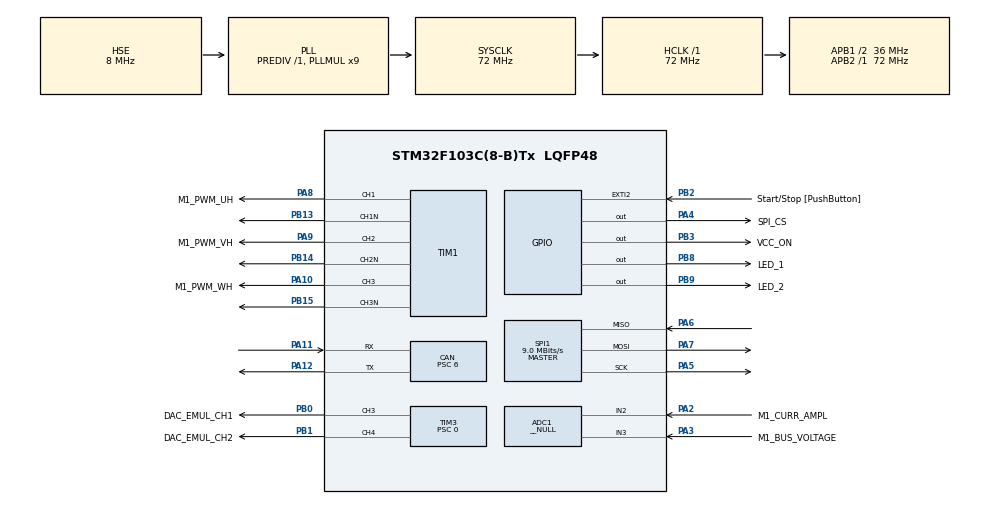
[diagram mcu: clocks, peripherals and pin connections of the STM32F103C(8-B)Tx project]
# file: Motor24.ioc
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ADC1.Channel-1\#ChannelInjectedConversion=ADC_CHANNEL_2
ADC1.Channel-1\#ChannelRegularConversion=ADC_CHANNEL_3
ADC1.Channel-2\#ChannelInjectedConversion=ADC_CHANNEL_2
ADC1.ContinuousConvMode=DISABLE
ADC1.DataAlign=ADC_DATAALIGN_LEFT
ADC1.DiscontinuousConvMode=DISABLE
ADC1.EnableAnalogWatchDog=false
ADC1.EnableInjectedConversion=ENABLE
ADC1.EnableRegularConversion=ENABLE
ADC1.ExternalTrigConv=ADC_SOFTWARE_START
ADC1.ExternalTrigConvEdge=ADC_EXTERNALTRIGCONVEDGE_NONE
ADC1.ExternalTrigInjecConv=ADC_EXTERNALTRIGINJECCONV_T4_TRGO
ADC1.ExternalTrigInjecConvEdge=ADC_EXTERNALTRIGINJECCONVEDGE_RISING
ADC1.InjNumberOfConversion=2
ADC1.InjectedConvMode=None
ADC1.InjectedOffset-1\#ChannelInjectedConversion=0
ADC1.InjectedOffset-2\#ChannelInjectedConversion=0
ADC1.Mode=__NULL
ADC1.NbrOfConversion=1
ADC1.NbrOfConversionFlag=1
ADC1.Offset-1\#ChannelRegularConversion=0
ADC1.OffsetNumber-1\#ChannelRegularConversion=ADC_OFFSET_NONE
ADC1.Rank-1\#ChannelInjectedConversion=1
ADC1.Rank-1\#ChannelRegularConversion=1
ADC1.Rank-2\#ChannelInjectedConversion=2
ADC1.SamplingTime-1\#ChannelInjectedConversion=ADC_SAMPLETIME_7CYCLES_5
ADC1.SamplingTime-1\#ChannelRegularConversion=ADC_SAMPLETIME_28CYCLES_5
ADC1.SamplingTime-2\#ChannelInjectedConversion=ADC_SAMPLETIME_7CYCLES_5
ADC1.ScanConvMode=ADC_SCAN_ENABLE
ADC1.master=1
CAN.BS1=CAN_BS1_3TQ
CAN.BS2=CAN_BS2_2TQ
CAN.CalculateTimeBit=1000
CAN.CalculateTimeQuantum=166.66666666666669
CAN.Prescaler=6
Dma.ADC1.2.Direction=DMA_PERIPH_TO_MEMORY
Dma.ADC1.2.Instance=DMA1_Channel1
Dma.ADC1.2.MemDataAlignment=DMA_MDATAALIGN_HALFWORD
Dma.ADC1.2.MemInc=DMA_MINC_DISABLE
Dma.ADC1.2.Mode=DMA_CIRCULAR
Dma.ADC1.2.PeriphDataAlignment=DMA_PDATAALIGN_HALFWORD
Dma.ADC1.2.PeriphInc=DMA_PINC_DISABLE
Dma.ADC1.2.Priority=DMA_PRIORITY_LOW
Dma.Request0=TIM1_UP
Dma.Request1=TIM1_CH4/TRIG/COM
Dma.Request2=ADC1
Dma.TIM1_CH4/TRIG/COM.1.Direction=DMA_MEMORY_TO_PERIPH
Dma.TIM1_CH4/TRIG/COM.1.Instance=DMA1_Channel4
Dma.TIM1_CH4/TRIG/COM.1.MemDataAlignment=DMA_MDATAALIGN_HALFWORD
Dma.TIM1_CH4/TRIG/COM.1.MemInc=DMA_MINC_ENABLE
Dma.TIM1_CH4/TRIG/COM.1.Mode=DMA_CIRCULAR
Dma.TIM1_CH4/TRIG/COM.1.PeriphDataAlignment=DMA_PDATAALIGN_HALFWORD
Dma.TIM1_CH4/TRIG/COM.1.PeriphInc=DMA_PINC_DISABLE
Dma.TIM1_CH4/TRIG/COM.1.Priority=DMA_PRIORITY_HIGH
Dma.TIM1_UP.0.Direction=DMA_MEMORY_TO_PERIPH
Dma.TIM1_UP.0.Instance=DMA1_Channel5
Dma.TIM1_UP.0.MemDataAlignment=DMA_MDATAALIGN_HALFWORD
Dma.TIM1_UP.0.MemInc=DMA_MINC_ENABLE
Dma.TIM1_UP.0.Mode=DMA_CIRCULAR
Dma.TIM1_UP.0.PeriphDataAlignment=DMA_PDATAALIGN_HALFWORD
Dma.TIM1_UP.0.PeriphInc=DMA_PINC_DISABLE
Dma.TIM1_UP.0.Priority=DMA_PRIORITY_HIGH
ExtraMW=MotorControl
ExtraMW.MotorControl.Config=MotorControl
ExtraMW.MotorControl.Mode=MotorControl
ExtraMW.MotorControl.Root=MCSDK_v5.3.3/MotorControl
ExtraMW.MotorControl.Template=templates
Mcu.Family=STM32F1
Mcu.Name=STM32F103C(8-B)Tx
Mcu.Package=LQFP48
MotorControl.ADC_1_PERIPH=ADC1
MotorControl.ADC_2_PERIPH=ADC2
MotorControl.ADC_AHBPERIPH=RCC_AHBPeriph_ADC12
MotorControl.ADC_CLOCK_WB_DIV=1
MotorControl.ADC_CLOCK_WB_FREQ=12
MotorControl.ADC_PERIPH=ADC1
MotorControl.ADC_REFERENCE_VOLTAGE=3.30
MotorControl.ALIGNMENT_ANGLE_DEG=90
MotorControl.ALIGNMENT_DURATION=700
MotorControl.AMPLIFICATION_GAIN=11.00
MotorControl.ANGC={0,0,0,0,0,0,0,0}
MotorControl.BEMF_CONSISTENCY_GAIN=64
MotorControl.BEMF_CONSISTENCY_TOL=64
MotorControl.BKIN1_FILTER=0
MotorControl.BKIN2_FILTER=0
MotorControl.BKIN2_MODE=NONE
MotorControl.BKIN_MODE=EXT_MODE
MotorControl.BOARD=CUSTOM
MotorControl.BRKIN2_GPIO_AF=GPIO_AF_2
MotorControl.BRKIN_GPIO_AF=GPIO_AF_2
MotorControl.BUS_VOLTAGE_READING=true
MotorControl.CLOCK_FREQUENCY=CPU_CLK_72_MHZ
MotorControl.CLOCK_SOURCE=EXTERNAL
MotorControl.CONSTANT1_D=2924
MotorControl.CONSTANT1_Q=2924
MotorControl.CONSTANT2_QD=3136
MotorControl.CORD_BEMF_CONSISTENCY_GAIN=64
MotorControl.CORD_BEMF_CONSISTENCY_TOL=64
MotorControl.CORD_F1=1024
MotorControl.CORD_F2=16384
MotorControl.CORD_FIFO_DEPTH_01HZ=64
MotorControl.CORD_FIFO_DEPTH_DPP=64
MotorControl.CORD_GAIN1=-410
MotorControl.CORD_GAIN2=4116
MotorControl.CORD_MAX_ACCEL_DPPP=810
MotorControl.CORD_MEAS_ERRORS_BEFORE_FAULTS=3
MotorControl.CORD_VARIANCE_THRESHOLD=4
MotorControl.CPU_CLK_72_MHZ=true
MotorControl.CTRBDID=10000
MotorControl.CURRENT_READING_TOPOLOGY=SINGLE_SHUNT
MotorControl.CURR_SAMPLING_TIME=7
MotorControl.DAC_EMULATED=true
MotorControl.DAC_FUNCTIONALITY=true
MotorControl.DAC_TIMER_CH1_GPIO_PIN=LL_GPIO_PIN_0
MotorControl.DAC_TIMER_CH1_GPIO_PORT=GPIOB
MotorControl.DAC_TIMER_CH2_GPIO_PIN=LL_GPIO_PIN_1
MotorControl.DAC_TIMER_CH2_GPIO_PORT=GPIOB
MotorControl.DAC_TIMER_REMAPPING=NO_REMAP
MotorControl.DAC_TIMER_SELECTION=TIM3
MotorControl.DC_CURRENT_RS_MEAS=1.50
MotorControl.DEBUG_DAC_CH1=true
MotorControl.DEBUG_DAC_CH2=true
MotorControl.DEFAULT_CONTROL_MODE=STC_SPEED_MODE
MotorControl.DEFAULT_DAC_CHANNEL_1=MC_PROTOCOL_REG_I_A
MotorControl.DEFAULT_DAC_CHANNEL_2=MC_PROTOCOL_REG_I_B
MotorControl.DEFAULT_DAC_MOTOR=0
MotorControl.DEFAULT_FLUX_COMPONENT=0
MotorControl.DEFAULT_TARGET_SPEED_RPM=700
MotorControl.DEFAULT_TORQUE_COMPONENT=0
MotorControl.DISSIPATIVE_BRAKE_POLARITY=DOUT_ACTIVE_HIGH
MotorControl.DRIVES_NUMBER_SELECTION=SINGLEDRIVE
MotorControl.EMERGENCY2_STOP_GPIO_PIN=LL_GPIO_PIN_12
MotorControl.EMERGENCY2_STOP_GPIO_PORT=GPIOB
MotorControl.EMERGENCY_STOP_GPIO_PIN=LL_GPIO_PIN_12
MotorControl.EMERGENCY_STOP_GPIO_PORT=GPIOB
MotorControl.ENABLE_SL_ALGO_FROM_PHASE=2
MotorControl.ENCODER_AVAILABLE=false
MotorControl.ENCODER_PPR=400
MotorControl.ENC_AVERAGING_FIFO_DEPTH=16
MotorControl.ENC_A_GPIO_PIN=LL_GPIO_PIN_0
MotorControl.ENC_A_GPIO_PORT=GPIOA
MotorControl.ENC_B_GPIO_PIN=LL_GPIO_PIN_1
MotorControl.ENC_B_GPIO_PORT=GPIOA
MotorControl.ENC_ICx_FILTER=50
MotorControl.ENC_INVERT_SPEED=false
MotorControl.ENC_MEAS_ERRORS_BEFORE_FAULTS=3
MotorControl.ENC_TIMER_REMAPPING=NO_REMAP_TIM2
MotorControl.ENC_TIMER_SELECTION=ENC_TIM2
MotorControl.EXT_CLK_8_MHZ=true
MotorControl.EXT_CLOCK_FREQUENCY=EXT_CLK_8_MHZ
MotorControl.F1=1024
MotorControl.F2=16384
MotorControl.FEEDBACK_NET_FILTERING=false
MotorControl.FEED_FORWARD_CURRENT_REG_ENABLING=false
MotorControl.FINAL_I_ALIGNMENT=4259
MotorControl.FLUX_WEAKENING_ENABLING=false
MotorControl.FW_KIDIV=32768
MotorControl.FW_KI_GAIN=5000
MotorControl.FW_KPDIV=32768
MotorControl.FW_KP_GAIN=3000
MotorControl.FW_VOLTAGE_REF=985
MotorControl.GAIN1=-410
MotorControl.GAIN2=4116
MotorControl.H1_GPIO_PIN=LL_GPIO_PIN_0
MotorControl.H1_GPIO_PORT=GPIOA
MotorControl.H2_GPIO_PIN=LL_GPIO_PIN_1
MotorControl.H2_GPIO_PORT=GPIOA
MotorControl.H3_GPIO_PIN=LL_GPIO_PIN_2
MotorControl.H3_GPIO_PORT=GPIOA
MotorControl.HALL_AVERAGING_FIFO_DEPTH=6
MotorControl.HALL_ICx_FILTER=94
MotorControl.HALL_MEAS_ERRORS_BEFORE_FAULTS=3
MotorControl.HALL_PHASE_SHIFT=300
MotorControl.HALL_SENSORS_AVAILABLE=false
MotorControl.HALL_SENSORS_PLACEMENT=DEGREES_120
MotorControl.HALL_TIMER_REMAPPING=NO_REMAP_TIM2
MotorControl.HALL_TIMER_SELECTION=HALL_TIM2
MotorControl.HFI_AMPLITUDE=25
MotorControl.HFI_DC_0_COEFF=0.00146
MotorControl.HFI_DC_1_COEFF=0.002921
MotorControl.HFI_DC_2_COEFF=0.00146
MotorControl.HFI_DC_3_COEFF=1.889033
MotorControl.HFI_DC_4_COEFF=-0.894874
MotorControl.HFI_DEBUG_MODE=false
MotorControl.HFI_FREQUENCY=400
MotorControl.HFI_HIFRAMPLSCAN=25
MotorControl.HFI_HP_ID_0_COEFF=0.883002
MotorControl.HFI_HP_ID_1_COEFF=-1.766004
MotorControl.HFI_HP_ID_2_COEFF=0.883002
MotorControl.HFI_HP_ID_3_COEFF=1.752268
MotorControl.HFI_HP_ID_4_COEFF=-0.779739
MotorControl.HFI_IDH_DELAY=32400
MotorControl.HFI_LOCKFREQ=66
MotorControl.HFI_LP_ID_0_COEFF=0.021558
MotorControl.HFI_LP_ID_1_COEFF=0.043117
MotorControl.HFI_LP_ID_2_COEFF=0.021558
MotorControl.HFI_LP_ID_3_COEFF=1.543836
MotorControl.HFI_LP_ID_4_COEFF=-0.63007
MotorControl.HFI_MAXANGLEDIFF=3640
MotorControl.HFI_MINIMUM_SPEED_RPM=402
MotorControl.HFI_NOTCH_IQD_0_COEFF=0.941467
MotorControl.HFI_NOTCH_IQD_1_COEFF=-1.823778
MotorControl.HFI_NOTCH_IQD_2_COEFF=0.941467
MotorControl.HFI_NOTCH_IQD_3_COEFF=1.823778
MotorControl.HFI_NOTCH_IQD_4_COEFF=-0.882933
MotorControl.HFI_NSDETPOINTSSKIP=10
MotorControl.HFI_NSMAXDETPOINTS=20
MotorControl.HFI_NS_MIN_SAT_DIFF=0
MotorControl.HFI_PID_KIDIV=32768
MotorControl.HFI_PID_KI_DEFAULT=400
MotorControl.HFI_PID_KPDIV=16384
MotorControl.HFI_PID_KP_DEFAULT=800
MotorControl.HFI_PLL_KI_DEFAULT=0.00400
MotorControl.HFI_PLL_KP_DEFAULT=0.00060
MotorControl.HFI_RESTARTTIMESEC=0.1
MotorControl.HFI_RESTART_RPM_TH=(((HFI_STO_RPM_TH)+(STO_HFI_RPM_TH))/2)
MotorControl.HFI_REVERT_DIRECTION=true
MotorControl.HFI_SCANROTATIONSNO=3
MotorControl.HFI_SPD_BUFFER_DEPTH_01HZ=64
MotorControl.HFI_STEPANGLE=3640
MotorControl.HFI_STO_RPM_TH=OBS_MINIMUM_SPEED_RPM
MotorControl.HFI_WAITAFTERNS2=4
MotorControl.HFI_WAITBEFORESN=6
MotorControl.HFI_WAITSYNCH=20
MotorControl.HFI_WAITTRACK=20
MotorControl.HIGH_SIDE_BRAKE_STATE=false
MotorControl.HIGH_SIDE_IDLE_STATE=false
MotorControl.HW_COMPLEMENTED_LOW_SIDE=true
MotorControl.HW_DEAD_TIME_NS=200
MotorControl.HW_OV_CURRENT_PROT_BYPASS=false
MotorControl.ID_DEMAG=-3276
MotorControl.INRUSH_CURRLIMIT_AT_POWER_ON=true
MotorControl.INRUSH_CURRLIMIT_CHANGE_AFTER_MS=1000
MotorControl.INRUSH_CURRLIMIT_ENABLING=false
MotorControl.INRUSH_CURRLIMIT_GPIO_PIN=LL_GPIO_PIN_4
MotorControl.INRUSH_CURRLIMIT_GPIO_PORT=GPIOD
MotorControl.INRUSH_CURR_LIMITER_POLARITY=DOUT_ACTIVE_HIGH
MotorControl.INTERNAL_OVERCURRENTPROTECTION=false
MotorControl.INTERNAL_OVERVOLTAGEPROTECTION=false
MotorControl.IQMAX=3276
MotorControl.LCD_JOYSTICK_FUNCTIONALITY=false
MotorControl.LCD_MODE=LCD_FULL
MotorControl.LDLQ_RATIO=1.000
MotorControl.LOW_SIDE_BRAKE_STATE=false
MotorControl.LOW_SIDE_IDLE_STATE=false
MotorControl.LOW_SIDE_SIGNALS_ENABLING=LS_DISABLED
MotorControl.LS=0.000030
MotorControl.MAX_APPLICATION_SPEED=1710
MotorControl.MAX_MODULATION_100_PER_CENT=true
MotorControl.MAX_MODULATION_INDEX=MAX_MODULATION_100_PER_CENT
MotorControl.MCU=STM32F103CB
MotorControl.MCU_TYPE=STM32F103x_MD
MotorControl.MC_WORKBENCH_VERSION=5.3.2.18569
MotorControl.MEAS_ERRORS_BEFORE_FAULTS=3
MotorControl.MIN_APPLICATION_SPEED=0
MotorControl.MOTOR_MAX_SPEED_RPM=1710
MotorControl.MOTOR_TYPE=PMSM
MotorControl.MOTOR_VOLTAGE_CONSTANT=10.4
MotorControl.MTPA_ENABLING=false
MotorControl.NB_CONSECUTIVE_TESTS=2
MotorControl.NOMINAL_BUS_VOLTAGE_V=23
MotorControl.NOMINAL_CURRENT=3276
MotorControl.OBS_MEAS_ERRORS_BEFORE_FAULTS=3
MotorControl.OBS_MINIMUM_SPEED_RPM=713
MotorControl.OCPA_INVERTINGINPUT=COMPX_InvertingInput_VREF
MotorControl.OCPA_INVERTINGINPUT_GPIO_PIN=LL_GPIO_PIN_4
MotorControl.OCPA_INVERTINGINPUT_GPIO_PORT=GPIOA
MotorControl.OCPA_INVERTINGINPUT_MODE=INT_MODE
MotorControl.OCPA_NONINVERTINGINPUT=COMP1_NonInvertingInput_PA1
MotorControl.OCPA_NONINVERTINGINPUT_GPIO_PIN=LL_GPIO_PIN_1
MotorControl.OCPA_NONINVERTINGINPUT_GPIO_PORT=GPIOA
MotorControl.OCPA_OUTPUT=COMP_Output_TIM1BKIN2
MotorControl.OCPA_OUTPUTPOL=COMP_OutputPol_NonInverted
MotorControl.OCPA_OUTPUT_GPIO_AF=GPIO_AF_8
MotorControl.OCPA_OUTPUT_GPIO_PIN=LL_GPIO_PIN_0
MotorControl.OCPA_OUTPUT_GPIO_PORT=GPIOA
MotorControl.OCPA_OUTPUT_MODE=INT_MODE
MotorControl.OCPA_SELECTION=COMP1
MotorControl.OCPB_INVERTINGINPUT=COMPX_InvertingInput_VREF
MotorControl.OCPB_INVERTINGINPUT_GPIO_PIN=LL_GPIO_PIN_4
MotorControl.OCPB_INVERTINGINPUT_GPIO_PORT=GPIOA
MotorControl.OCPB_INVERTINGINPUT_MODE=INT_MODE
MotorControl.OCPB_NONINVERTINGINPUT=COMP2_NonInvertingInput_PA7
MotorControl.OCPB_NONINVERTINGINPUT_GPIO_PIN=LL_GPIO_PIN_7
MotorControl.OCPB_NONINVERTINGINPUT_GPIO_PORT=GPIOA
MotorControl.OCPB_OUTPUT=COMP_Output_TIM1BKIN2
MotorControl.OCPB_OUTPUTPOL=COMP_OutputPol_NonInverted
MotorControl.OCPB_OUTPUT_GPIO_AF=GPIO_AF_8
MotorControl.OCPB_OUTPUT_GPIO_PIN=LL_GPIO_PIN_2
MotorControl.OCPB_OUTPUT_GPIO_PORT=GPIOA
MotorControl.OCPB_OUTPUT_MODE=INT_MODE
MotorControl.OCPB_SELECTION=COMP2
MotorControl.OCPC_INVERTINGINPUT=COMPX_InvertingInput_VREF
MotorControl.OCPC_INVERTINGINPUT_GPIO_PIN=LL_GPIO_PIN_4
MotorControl.OCPC_INVERTINGINPUT_GPIO_PORT=GPIOA
MotorControl.OCPC_INVERTINGINPUT_MODE=INT_MODE
MotorControl.OCPC_NONINVERTINGINPUT=COMP3_NonInvertingInput_PD14
MotorControl.OCPC_NONINVERTINGINPUT_GPIO_PIN=LL_GPIO_PIN_14
MotorControl.OCPC_NONINVERTINGINPUT_GPIO_PORT=GPIOD
MotorControl.OCPC_OUTPUT=COMP_Output_TIM1BKIN2
MotorControl.OCPC_OUTPUTPOL=COMP_OutputPol_NonInverted
MotorControl.OCPC_OUTPUT_GPIO_AF=GPIO_AF_7
MotorControl.OCPC_OUTPUT_GPIO_PIN=LL_GPIO_PIN_8
MotorControl.OCPC_OUTPUT_GPIO_PORT=GPIOC
MotorControl.OCPC_OUTPUT_MODE=INT_MODE
MotorControl.OCPC_SELECTION=COMP3
MotorControl.OCPREF=23830
MotorControl.OCP_COMP_THRESHOLD=0.80
MotorControl.OCP_FILTER=COMP_Mode_HighSpeed
MotorControl.OCP_INVERTINGINPUT=COMPX_InvertingInput_VREF
MotorControl.OCP_INVERTINGINPUT_GPIO_PIN=LL_GPIO_PIN_4
MotorControl.OCP_INVERTINGINPUT_GPIO_PORT=GPIOA
MotorControl.OCP_INVERTINGINPUT_MODE=INT_MODE
MotorControl.OCP_NONINVERTINGINPUT=COMP2_NonInvertingInput_PA7
MotorControl.OCP_NONINVERTINGINPUT_GPIO_PIN=LL_GPIO_PIN_7
MotorControl.OCP_NONINVERTINGINPUT_GPIO_PORT=GPIOA
MotorControl.OCP_OUTPUT=COMP_Output_TIM1BKIN2
MotorControl.OCP_OUTPUTPOL=COMP_OutputPol_NonInverted
MotorControl.OCP_OUTPUT_GPIO_AF=GPIO_AF_8
MotorControl.OCP_OUTPUT_GPIO_PIN=LL_GPIO_PIN_2
MotorControl.OCP_OUTPUT_GPIO_PORT=GPIOA
MotorControl.OCP_OUTPUT_MODE=INT_MODE
MotorControl.OCP_SELECTION=COMP2
MotorControl.OFST={0,0,0,0,0,0,0,0}
MotorControl.ON_OVER_VOLTAGE=TURN_OFF_PWM
MotorControl.OPAMP1_INVERTINGINPUT=OPAMP1_InvertingInput_PGA
MotorControl.OPAMP1_INVERTINGINPUT_GPIO_PIN=LL_GPIO_PIN_3
MotorControl.OPAMP1_INVERTINGINPUT_GPIO_PORT=GPIOA
MotorControl.OPAMP1_INVERTINGINPUT_MODE=INT_MODE
MotorControl.OPAMP1_NONINVERTINGINPUT_PHA=OPAMP1_NonInvertingInput_PA1
MotorControl.OPAMP1_NONINVERTINGINPUT_PHA_GPIO_PIN=LL_GPIO_PIN_1
MotorControl.OPAMP1_NONINVERTINGINPUT_PHA_GPIO_PORT=GPIOA
MotorControl.OPAMP1_NONINVERTINGINPUT_PHB=OPAMP1_NonInvertingInput_PA7
MotorControl.OPAMP1_NONINVERTINGINPUT_PHB_GPIO_PIN=LL_GPIO_PIN_7
MotorControl.OPAMP1_NONINVERTINGINPUT_PHB_GPIO_PORT=GPIOA
MotorControl.OPAMP1_OUT_GPIO_PIN=LL_GPIO_PIN_2
MotorControl.OPAMP1_OUT_GPIO_PORT=GPIOA
MotorControl.OPAMP1_SELECTION=OPAMP1
MotorControl.OPAMP2_INVERTINGINPUT=OPAMP2_InvertingInput_PGA
MotorControl.OPAMP2_INVERTINGINPUT_GPIO_PIN=LL_GPIO_PIN_5
MotorControl.OPAMP2_INVERTINGINPUT_GPIO_PORT=GPIOC
MotorControl.OPAMP2_INVERTINGINPUT_MODE=INT_MODE
MotorControl.OPAMP2_NONINVERTINGINPUT_PHA=OPAMP2_NonInvertingInput_PD14
MotorControl.OPAMP2_NONINVERTINGINPUT_PHA_GPIO_PIN=LL_GPIO_PIN_14
MotorControl.OPAMP2_NONINVERTINGINPUT_PHA_GPIO_PORT=GPIOD
MotorControl.OPAMP2_NONINVERTINGINPUT_PHB=OPAMP2_NonInvertingInput_PA7
MotorControl.OPAMP2_NONINVERTINGINPUT_PHB_GPIO_PIN=LL_GPIO_PIN_7
MotorControl.OPAMP2_NONINVERTINGINPUT_PHB_GPIO_PORT=GPIOA
MotorControl.OPAMP2_NONINVERTINGINPUT_PHC=OPAMP2_NonInvertingInput_PD14
MotorControl.OPAMP2_NONINVERTINGINPUT_PHC_GPIO_PIN=LL_GPIO_PIN_14
MotorControl.OPAMP2_NONINVERTINGINPUT_PHC_GPIO_PORT=GPIOD
MotorControl.OPAMP2_OUT_GPIO_PIN=LL_GPIO_PIN_6
MotorControl.OPAMP2_OUT_GPIO_PORT=GPIOA
MotorControl.OPAMP2_SELECTION=OPAMP2
MotorControl.OPAMP_INVERTINGINPUT=OPAMP1_InvertingInput_PGA
MotorControl.OPAMP_INVERTINGINPUT_GPIO_PIN=LL_GPIO_PIN_3
MotorControl.OPAMP_INVERTINGINPUT_GPIO_PORT=GPIOA
MotorControl.OPAMP_INVERTINGINPUT_MODE=INT_MODE
MotorControl.OPAMP_NONINVERTINGINPUT=OPAMP1_NonInvertingInput_PA7
MotorControl.OPAMP_NONINVERTINGINPUT_GPIO_PIN=LL_GPIO_PIN_7
MotorControl.OPAMP_NONINVERTINGINPUT_GPIO_PORT=GPIOA
MotorControl.OPAMP_OUT_GPIO_PIN=LL_GPIO_PIN_2
MotorControl.OPAMP_OUT_GPIO_PORT=GPIOA
MotorControl.OPAMP_PGACONNECT=OPAMP_PGAConnect_No
MotorControl.OPAMP_PGAGAIN=OPAMP_OPAMP_PGAGain_2
MotorControl.OPAMP_SELECTION=OPAMP1
MotorControl.OPAMP_TYPE_GAIN=INTERNAL
MotorControl.OPEN_LOOP_FOC=false
MotorControl.OPEN_LOOP_K=44
MotorControl.OPEN_LOOP_OFF=4400
MotorControl.OPEN_LOOP_SPEED_RAMP_DURATION_MS=1000
MotorControl.OPEN_LOOP_SPEED_RPM=100
MotorControl.OPEN_LOOP_VF=false
MotorControl.OPEN_LOOP_VOLTAGE_d=6000
MotorControl.OVERCURR_FEEDBACK_POLARITY=EMSTOP_ACTIVE_LOW
MotorControl.OVERCURR_PROTECTION_HW_DISABLING=DOUT_ACTIVE_HIGH
MotorControl.OVPREF=23830
MotorControl.OVP_FILTER=COMP_Mode_HighSpeed
MotorControl.OVP_INVERTINGINPUT=COMPX_InvertingInput_VREF
MotorControl.OVP_INVERTINGINPUT_GPIO_PIN=LL_GPIO_PIN_4
MotorControl.OVP_INVERTINGINPUT_GPIO_PORT=GPIOA
MotorControl.OVP_INVERTINGINPUT_MODE=INT_MODE
MotorControl.OVP_NONINVERTINGINPUT=COMP7_NonInvertingInput_PA0
MotorControl.OVP_NONINVERTINGINPUT_GPIO_PIN=LL_GPIO_PIN_0
MotorControl.OVP_NONINVERTINGINPUT_GPIO_PORT=GPIOA
MotorControl.OVP_OUTPUT=COMP_Output_TIM1BKIN
MotorControl.OVP_OUTPUTPOL=COMP_OutputPol_NonInverted
MotorControl.OVP_OUTPUT_GPIO_AF=GPIO_AF_3
MotorControl.OVP_OUTPUT_GPIO_PIN=LL_GPIO_PIN_2
MotorControl.OVP_OUTPUT_GPIO_PORT=GPIOC
MotorControl.OVP_OUTPUT_MODE=INT_MODE
MotorControl.OVP_SELECTION=COMP7
MotorControl.OV_CURR_BYPASS_GPIO_PIN=LL_GPIO_PIN_5
MotorControl.OV_CURR_BYPASS_GPIO_PORT=GPIOD
MotorControl.OV_TEMPERATURE_HYSTERESIS_C=10
MotorControl.OV_TEMPERATURE_PROT_ENABLING=false
MotorControl.OV_TEMPERATURE_THRESHOLD_C=70
MotorControl.OV_VOLTAGE_PROT_ENABLING=true
MotorControl.OV_VOLTAGE_THRESHOLD_V=35
MotorControl.PHASE1_DURATION=1000
MotorControl.PHASE1_FINAL_CURRENT=3276
MotorControl.PHASE1_FINAL_SPEED_RPM=0
MotorControl.PHASE2_DURATION=1584
MotorControl.PHASE2_FINAL_CURRENT=3276
MotorControl.PHASE2_FINAL_SPEED_RPM=792
MotorControl.PHASE3_DURATION=0
MotorControl.PHASE3_FINAL_CURRENT=3276
MotorControl.PHASE3_FINAL_SPEED_RPM=792
MotorControl.PHASE4_DURATION=0
MotorControl.PHASE4_FINAL_CURRENT=3276
MotorControl.PHASE4_FINAL_SPEED_RPM=792
MotorControl.PHASE5_DURATION=0
MotorControl.PHASE5_FINAL_CURRENT=3276
MotorControl.PHASE5_FINAL_SPEED_RPM=792
MotorControl.PHASE_CURRENTS_ADC=ADC1_2
MotorControl.PHASE_CURRENTS_CHANNEL=ADC_CHANNEL_2
MotorControl.PHASE_CURRENTS_GPIO_PIN=LL_GPIO_PIN_2
MotorControl.PHASE_CURRENTS_GPIO_PORT=GPIOA
MotorControl.PHASE_UH_GPIO_AF=GPIO_AF_6
MotorControl.PHASE_UH_GPIO_PIN=LL_GPIO_PIN_8
MotorControl.PHASE_UH_GPIO_PORT=GPIOA
MotorControl.PHASE_UH_POLARITY=H_ACTIVE_HIGH
MotorControl.PHASE_UL_GPIO_AF=GPIO_AF_0
MotorControl.PHASE_UL_GPIO_PIN=LL_GPIO_PIN_13
MotorControl.PHASE_UL_GPIO_PORT=GPIOC
MotorControl.PHASE_UL_POLARITY=L_ACTIVE_LOW
MotorControl.PHASE_U_CURR_ADC=ADC1_2
MotorControl.PHASE_U_CURR_CHANNEL=ADC_CHANNEL_8
MotorControl.PHASE_U_GPIO_PIN=LL_GPIO_PIN_0
MotorControl.PHASE_U_GPIO_PORT=GPIOB
MotorControl.PHASE_VH_GPIO_AF=GPIO_AF_6
MotorControl.PHASE_VH_GPIO_PIN=LL_GPIO_PIN_9
MotorControl.PHASE_VH_GPIO_PORT=GPIOA
MotorControl.PHASE_VH_POLARITY=H_ACTIVE_HIGH
MotorControl.PHASE_VL_GPIO_AF=GPIO_AF_0
MotorControl.PHASE_VL_GPIO_PIN=LL_GPIO_PIN_13
MotorControl.PHASE_VL_GPIO_PORT=GPIOC
MotorControl.PHASE_VL_POLARITY=L_ACTIVE_LOW
MotorControl.PHASE_V_CURR_ADC=ADC1_2
MotorControl.PHASE_V_CURR_CHANNEL=ADC_CHANNEL_9
MotorControl.PHASE_V_GPIO_PIN=LL_GPIO_PIN_1
MotorControl.PHASE_V_GPIO_PORT=GPIOB
MotorControl.PHASE_WH_GPIO_AF=GPIO_AF_6
MotorControl.PHASE_WH_GPIO_PIN=LL_GPIO_PIN_10
MotorControl.PHASE_WH_GPIO_PORT=GPIOA
MotorControl.PHASE_WH_POLARITY=H_ACTIVE_HIGH
MotorControl.PHASE_WL_GPIO_AF=GPIO_AF_0
MotorControl.PHASE_WL_GPIO_PIN=LL_GPIO_PIN_13
MotorControl.PHASE_WL_GPIO_PORT=GPIOC
MotorControl.PHASE_WL_POLARITY=L_ACTIVE_LOW
MotorControl.PHASE_W_CURR_ADC=ADC1_2
MotorControl.PHASE_W_CURR_CHANNEL=ADC_CHANNEL_6
MotorControl.PHASE_W_GPIO_PIN=LL_GPIO_PIN_6
MotorControl.PHASE_W_GPIO_PORT=GPIOA
MotorControl.PID_FLUX_KD_DEFAULT=100
MotorControl.PID_FLUX_KI_DEFAULT=2821
MotorControl.PID_FLUX_KP_DEFAULT=3847
MotorControl.PID_SPEED_KD_DEFAULT=0
MotorControl.PID_SPEED_KI_DEFAULT=814
MotorControl.PID_SPEED_KP_DEFAULT=2586
MotorControl.PID_TORQUE_KD_DEFAULT=100
MotorControl.PID_TORQUE_KI_DEFAULT=2821
MotorControl.PID_TORQUE_KP_DEFAULT=3847
MotorControl.PLL_KI_GAIN=135
MotorControl.PLL_KP_GAIN=1910
MotorControl.POLE_PAIR_NUM=21
MotorControl.PWBDID=10000
MotorControl.PWM_FREQUENCY=10000
MotorControl.PWM_TIMER_REMAPPING=PWM_NO_REMAP
MotorControl.PWM_TIMER_SELECTION=PWM_TIM1
MotorControl.REGCONVADC=ADC1
MotorControl.REGULATION_EXECUTION_RATE=1
MotorControl.RS=0.44
MotorControl.RSHUNT=0.010
MotorControl.R_BRAKE_GPIO_PIN=LL_GPIO_PIN_5
MotorControl.R_BRAKE_GPIO_PORT=GPIOD
MotorControl.R_BRAKE_SWITCH_OFF_THRES_V=28
MotorControl.SEGDIV=0
MotorControl.SERIAL_COMMUNICATION=false
MotorControl.SERIAL_COM_CHANNEL1=MC_PROTOCOL_REG_I_A
MotorControl.SERIAL_COM_CHANNEL2=MC_PROTOCOL_REG_I_A
MotorControl.SERIAL_COM_MODE=COM_BIDIRECTIONAL
MotorControl.SERIAL_COM_MOTOR=0
MotorControl.SHARED_SIGNAL_ENABLE=false
MotorControl.SINGLEDRIVE=true
MotorControl.SINGLE_SHUNT=true
MotorControl.SPD_DIFFERENTIAL_TERM_ENABLING=false
MotorControl.SPEED_BAND_LOWER_LIMIT=15
MotorControl.SPEED_BAND_UPPER_LIMIT=17
MotorControl.SPEED_FEEDBACK_CHECK=true
MotorControl.SPEED_LOOP_FREQUENCY_HZ=1000
MotorControl.SPEED_SENSOR_SELECTION=STATE_OBSERVER_PLL
MotorControl.SP_KDDIV=16
MotorControl.SP_KIDIV=16384
MotorControl.SP_KPDIV=64
MotorControl.STARTING_ANGLE_DEG=0
MotorControl.START_STOP_BTN=true
MotorControl.START_STOP_GPIO_PIN=LL_GPIO_PIN_2
MotorControl.START_STOP_GPIO_PORT=GPIOB
MotorControl.START_STOP_POLARITY=DIN_ACTIVE_LOW
MotorControl.START_STOP_POLARITY_EDGE=GPIO_NOPULL
MotorControl.STATE_OBSERVER_PLL=true
MotorControl.STM32F103x_MD=true
MotorControl.STO_FIFO_DEPTH_01HZ=64
MotorControl.STO_FIFO_DEPTH_DPP=64
MotorControl.STO_HFI_RPM_TH=460
MotorControl.SW_DEADTIME_NS=800
MotorControl.SW_OV_CURRENT_PROT_ENABLING=true
MotorControl.T0_C=25
MotorControl.TEMPERATURE_READING=false
MotorControl.TEMP_ADC_SAMPLING_TIME=1
MotorControl.TEMP_FDBK_ADC=ADC1
MotorControl.TEMP_FDBK_CHANNEL=ADC_CHANNEL_9
MotorControl.TEMP_FDBK_GPIO_PIN=LL_GPIO_PIN_1
MotorControl.TEMP_FDBK_GPIO_PORT=GPIOB
MotorControl.TFDIFFERENTIAL_TERM_ENABLING=false
MotorControl.TF_KDDIV=8192
MotorControl.TF_KIDIV=8192
MotorControl.TF_KPDIV=16384
MotorControl.TNOISE_NS=2550
MotorControl.TRANSITION_DURATION=25
MotorControl.TRISE_NS=800
MotorControl.T_MAX=70
MotorControl.UD_VOLTAGE_THRESHOLD_V=15
MotorControl.USART_REMAPPING=NO_REMAP_USART1
MotorControl.USART_RX_GPIO_PIN=LL_GPIO_PIN_10
MotorControl.USART_RX_GPIO_PORT=GPIOA
MotorControl.USART_SELECTION=USE_USART1
MotorControl.USART_SPEED=115200
MotorControl.USART_TX_GPIO_PIN=LL_GPIO_PIN_9
MotorControl.USART_TX_GPIO_PORT=GPIOA
MotorControl.USE_INTERNAL_OPAMP=false
MotorControl.UV_VOLTAGE_PROT_ENABLING=true
MotorControl.V0_V=0.290
MotorControl.VARIANCE_THRESHOLD=0.1
MotorControl.VBUS_ADC=ADC1
MotorControl.VBUS_ADC_SAMPLING_TIME=28
MotorControl.VBUS_CHANNEL=ADC_CHANNEL_3
MotorControl.VBUS_GPIO_PIN=LL_GPIO_PIN_3
MotorControl.VBUS_GPIO_PORT=GPIOA
MotorControl.VBUS_PARTITIONING_FACTOR=0.0208
MotorControl.WB_to_Mx_template_version=19-01-16
MotorControl.WB_to_Mx_version=0.15.6
MotorControl.dV_dT=0.025
NVIC.ADC1_2_IRQn=true\:2\:0\:true\:true\:false\:1\:false
NVIC.CAN1_RX1_IRQn=true\:0\:0\:false\:false\:true\:true
NVIC.DMA1_Channel1_IRQn=true\:0\:0\:true\:true\:false\:6\:true
NVIC.DMA1_Channel4_IRQn=true\:0\:0\:true\:true\:false\:5\:true
NVIC.DMA1_Channel5_IRQn=true\:0\:0\:true\:true\:false\:4\:true
NVIC.EXTI2_IRQn=true\:0\:0\:false\:true\:false\:7\:true
NVIC.PriorityGroup=NVIC_PRIORITYGROUP_3
NVIC.TIM1_BRK_IRQn=true\:4\:1\:false\:true\:false\:3\:true
NVIC.TIM1_UP_IRQn=true\:0\:0\:false\:true\:false\:2\:true
PA10.GPIO_Label=M1_PWM_WH
PA10.GPIO_PuPd=GPIO_PULLDOWN
PA10.GPIO_Speed=GPIO_SPEED_FREQ_HIGH
PA10.Signal=S_TIM1_CH3
PA11.Mode=Master
PA11.Signal=CAN_RX
PA12.Mode=Master
PA12.Signal=CAN_TX
PA13.Mode=Serial_Wire
PA13.Signal=SYS_JTMS-SWDIO
PA14.Mode=Serial_Wire
PA14.Signal=SYS_JTCK-SWCLK
PA2.GPIO_Label=M1_CURR_AMPL
PA2.Signal=SharedAnalog_PA2
PA3.GPIO_Label=M1_BUS_VOLTAGE
PA3.Signal=ADCx_IN3
PA4.GPIO_Label=SPI_CS
PA4.PinState=GPIO_PIN_SET
PA4.Signal=GPIO_Output
PA5.Mode=Full_Duplex_Master
PA5.Signal=SPI1_SCK
PA6.Mode=Full_Duplex_Master
PA6.Signal=SPI1_MISO
PA7.Mode=Full_Duplex_Master
PA7.Signal=SPI1_MOSI
PA8.GPIO_Label=M1_PWM_UH
PA8.GPIO_PuPd=GPIO_PULLDOWN
PA8.GPIO_Speed=GPIO_SPEED_FREQ_HIGH
PA8.Signal=S_TIM1_CH1
PA9.GPIO_Label=M1_PWM_VH
PA9.GPIO_PuPd=GPIO_PULLDOWN
PA9.GPIO_Speed=GPIO_SPEED_FREQ_HIGH
PA9.Signal=S_TIM1_CH2
PB0.GPIO_Label=DAC_EMUL_CH1
PB0.Signal=S_TIM3_CH3
PB1.GPIO_Label=DAC_EMUL_CH2
PB1.Signal=S_TIM3_CH4
PB13.Mode=PWM Generation1 CH1 CH1N
PB13.Signal=TIM1_CH1N
PB14.Mode=PWM Generation2 CH2 CH2N
PB14.Signal=TIM1_CH2N
PB15.Mode=PWM Generation3 CH3 CH3N
PB15.Signal=TIM1_CH3N
PB2.GPIO_Label=Start/Stop [PushButton]
PB2.GPIO_ModeDefaultEXTI=GPIO_MODE_IT_FALLING
PB2.GPIO_PuPd=GPIO_NOPULL
PB2.Signal=GPXTI2
PB3.GPIO_Label=VCC_ON
PB3.PinState=GPIO_PIN_RESET
PB3.Signal=GPIO_Output
PB8.GPIO_Label=LED_1
PB8.PinState=GPIO_PIN_SET
PB8.Signal=GPIO_Output
PB9.GPIO_Label=LED_2
PB9.PinState=GPIO_PIN_SET
PB9.Signal=GPIO_Output
PD0-OSC_IN.Mode=HSE-External-Oscillator
PD0-OSC_IN.Signal=RCC_OSC_IN
PD1-OSC_OUT.Mode=HSE-External-Oscillator
PD1-OSC_OUT.Signal=RCC_OSC_OUT
ProjectManager.HeapSize=0x200
ProjectManager.StackSize=0x400
ProjectManager.TargetToolchain=MDK-ARM V5
RCC.ADCPresc=RCC_ADCPCLK2_DIV6
RCC.AHBFreq_Value=72000000
RCC.APB1CLKDivider=RCC_HCLK_DIV2
RCC.APB1Freq_Value=36000000
RCC.APB1TimFreq_Value=72000000
RCC.APB2Freq_Value=72000000
RCC.APB2TimFreq_Value=72000000
RCC.EnbaleCSS=true
RCC.HCLKFreq_Value=72000000
RCC.PLLMUL=RCC_PLL_MUL9
RCC.PLLSourceVirtual=RCC_PLLSOURCE_HSE
RCC.RTCClockSelection=RCC_RTCCLKSOURCE_LSE
RCC.SYSCLKFreq_VALUE=72000000
RCC.SYSCLKSource=RCC_SYSCLKSOURCE_PLLCLK
RCC.USBFreq_Value=72000000
SH.ADCx_IN3.0=ADC1_IN3,IN3
SH.S_TIM1_CH1.0=TIM1_CH1,PWM Generation1 CH1 CH1N
SH.S_TIM1_CH2.0=TIM1_CH2,PWM Generation2 CH2 CH2N
SH.S_TIM1_CH3.0=TIM1_CH3,PWM Generation3 CH3 CH3N
SH.S_TIM3_CH3.0=TIM3_CH3,PWM Generation3 CH3
SH.S_TIM3_CH4.0=TIM3_CH4,PWM Generation4 CH4
SH.SharedAnalog_PA2.0=ADC1_IN2,IN2
SPI1.BaudRatePrescaler=SPI_BAUDRATEPRESCALER_8
SPI1.CalculateBaudRate=9.0 MBits/s
SPI1.Direction=SPI_DIRECTION_2LINES
SPI1.Mode=SPI_MODE_MASTER
SPI1.VirtualType=VM_MASTER
TIM1.AutomaticOutput=TIM_AUTOMATICOUTPUT_DISABLE
TIM1.BreakPolarity=TIM_BREAKPOLARITY_LOW
TIM1.BreakState=TIM_BREAK_ENABLE
TIM1.Channel-PWM\ Generation1\ CH1\ CH1N=TIM_CHANNEL_1
TIM1.Channel-PWM\ Generation2\ CH2\ CH2N=TIM_CHANNEL_2
TIM1.Channel-PWM\ Generation3\ CH3\ CH3N=TIM_CHANNEL_3
TIM1.Channel-PWM\ Generation4\ No\ Output=TIM_CHANNEL_4
TIM1.ClockDivision=TIM_CLOCKDIVISION_DIV2
TIM1.CounterMode=TIM_COUNTERMODE_CENTERALIGNED3
TIM1.LockLevel=TIM_LOCKLEVEL_1
TIM1.OCIdleState_1=TIM_OCIDLESTATE_RESET
TIM1.OCIdleState_2=TIM_OCIDLESTATE_RESET
TIM1.OCIdleState_3=TIM_OCIDLESTATE_RESET
TIM1.OCMode_PWM-PWM\ Generation4\ No\ Output=TIM_OCMODE_PWM2
TIM1.OCPolarity_1=TIM_OCPOLARITY_HIGH
TIM1.OCPolarity_2=TIM_OCPOLARITY_HIGH
TIM1.OCPolarity_3=TIM_OCPOLARITY_HIGH
TIM1.OffStateIDLEMode=TIM_OSSI_ENABLE
TIM1.OffStateRunMode=TIM_OSSR_ENABLE
TIM1.Period=((PWM_PERIOD_CYCLES) / 2)
TIM1.Prescaler=((TIM_CLOCK_DIVIDER) - 1)
TIM1.Pulse-PWM\ Generation4\ No\ Output=(((PWM_PERIOD_CYCLES) / 2) - (HTMIN))
TIM1.RepetitionCounter=(REP_COUNTER)
TIM1.TIM_MasterOutputTrigger=TIM_TRGO_UPDATE
TIM1.TIM_MasterSlaveMode=TIM_MASTERSLAVEMODE_DISABLE
TIM3.AutoReloadPreload=TIM_AUTORELOAD_PRELOAD_DISABLE
TIM3.Channel-PWM\ Generation3\ CH3=TIM_CHANNEL_3
TIM3.Channel-PWM\ Generation4\ CH4=TIM_CHANNEL_4
TIM3.ClockDivision=TIM_CLOCKDIVISION_DIV1
TIM3.CounterMode=TIM_COUNTERMODE_UP
TIM3.OCFastMode_PWM-PWM\ Generation3\ CH3=TIM_OCFAST_DISABLE
TIM3.OCFastMode_PWM-PWM\ Generation4\ CH4=TIM_OCFAST_DISABLE
TIM3.OCMode_PWM-PWM\ Generation3\ CH3=TIM_OCMODE_PWM1
TIM3.OCMode_PWM-PWM\ Generation4\ CH4=TIM_OCMODE_PWM1
TIM3.OCPolarity_3=TIM_OCPOLARITY_HIGH
TIM3.OCPolarity_4=TIM_OCPOLARITY_HIGH
TIM3.Period=0x800
TIM3.Prescaler=0
TIM3.Pulse-PWM\ Generation3\ CH3=0x400
TIM3.Pulse-PWM\ Generation4\ CH4=0x400
TIM3.TIM_MasterOutputTrigger=TIM_TRGO_RESET
TIM3.TIM_MasterSlaveMode=TIM_MASTERSLAVEMODE_DISABLE
TIM4.Channel-PWM\ Generation3\ No\ Output=TIM_CHANNEL_3
TIM4.ClockDivision=TIM_CLOCKDIVISION_DIV2
TIM4.OCMode_PWM-PWM\ Generation3\ No\ Output=TIM_OCMODE_PWM2
TIM4.Period=((PWM_PERIOD_CYCLES) - 1)
TIM4.Prescaler=((TIM_CLOCK_DIVIDER) - 1)
TIM4.Pulse-PWM\ Generation3\ No\ Output=0
TIM4.TIM_MasterOutputTrigger=TIM_TRGO_OC3REF
VP_MotorControl_MC_ENABLED.Mode=Enabled
VP_TIM1_VS_ClockSourceITR.Mode=TriggerSource_ITR1
VP_TIM1_VS_ControllerModeTrigger.Mode=Trigger Mode
VP_TIM1_VS_no_output4.Mode=PWM Generation4 No Output
VP_TIM4_VS_ClockSourceITR.Mode=TriggerSource_ITR1
VP_TIM4_VS_ControllerModeTrigger.Mode=Trigger Mode
VP_TIM4_VS_no_output3.Mode=PWM Generation3 No Output
board=custom

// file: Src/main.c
/* USER CODE BEGIN Header */
/**
  ******************************************************************************
  * @file           : main.c
  * @brief          : Main program body
  ******************************************************************************
  * This notice applies to any and all portions of this file
  * that are not between comment pairs USER CODE BEGIN and
  * USER CODE END. Other portions of this file, whether
  * inserted by the user or by software development tools
  * are owned by their respective copyright owners.
  *
  * Copyright (c) 2019 STMicroelectronics International N.V.
  * All rights reserved.
  *
  * Redistribution and use in source and binary forms, with or without
  * modification, are permitted, provided that the following conditions are met:
  *
  * 1. Redistribution of source code must retain the above copyright notice,
  *    this list of conditions and the following disclaimer.
  * 2. Redistributions in binary form must reproduce the above copyright notice,
  *    this list of conditions and the following disclaimer in the documentation
  *    and/or other materials provided with the distribution.
  * 3. Neither the name of STMicroelectronics nor the names of other
  *    contributors to this software may be used to endorse or promote products
  *    derived from this software without specific written permission.
  * 4. This software, including modifications and/or derivative works of this
  *    software, must execute solely and exclusively on microcontroller or
  *    microprocessor devices manufactured by or for STMicroelectronics.
  * 5. Redistribution and use of this software other than as permitted under
  *    this license is void and will automatically terminate your rights under
  *    this license.
  *
  * THIS SOFTWARE IS PROVIDED BY STMICROELECTRONICS AND CONTRIBUTORS "AS IS"
  * AND ANY EXPRESS, IMPLIED OR STATUTORY WARRANTIES, INCLUDING, BUT NOT
  * LIMITED TO, THE IMPLIED WARRANTIES OF MERCHANTABILITY, FITNESS FOR A
  * PARTICULAR PURPOSE AND NON-INFRINGEMENT OF THIRD PARTY INTELLECTUAL PROPERTY
  * RIGHTS ARE DISCLAIMED TO THE FULLEST EXTENT PERMITTED BY LAW. IN NO EVENT
  * SHALL STMICROELECTRONICS OR CONTRIBUTORS BE LIABLE FOR ANY DIRECT, INDIRECT,
  * INCIDENTAL, SPECIAL, EXEMPLARY, OR CONSEQUENTIAL DAMAGES (INCLUDING, BUT NOT
  * LIMITED TO, PROCUREMENT OF SUBSTITUTE GOODS OR SERVICES; LOSS OF USE, DATA,
  * OR PROFITS; OR BUSINESS INTERRUPTION) HOWEVER CAUSED AND ON ANY THEORY OF
  * LIABILITY, WHETHER IN CONTRACT, STRICT LIABILITY, OR TORT (INCLUDING
  * NEGLIGENCE OR OTHERWISE) ARISING IN ANY WAY OUT OF THE USE OF THIS SOFTWARE,
  * EVEN IF ADVISED OF THE POSSIBILITY OF SUCH DAMAGE.
  *
  ******************************************************************************
  */
/* USER CODE END Header */

#include "main.h"
#include "motorcontrol.h"

ADC_HandleTypeDef hadc1;
DMA_HandleTypeDef hdma_adc1;

CAN_HandleTypeDef hcan;

SPI_HandleTypeDef hspi1;

TIM_HandleTypeDef htim1;
TIM_HandleTypeDef htim3;
TIM_HandleTypeDef htim4;
DMA_HandleTypeDef hdma_tim1_up;
DMA_HandleTypeDef hdma_tim1_ch4_trig_com;

/* USER CODE BEGIN PV */
#include "tle5012b.h"
/* USER CODE END PV */

void SystemClock_Config(void);
static void MX_GPIO_Init(void);
static void MX_DMA_Init(void);
static void MX_SPI1_Init(void);
static void MX_CAN_Init(void);
static void MX_ADC1_Init(void);
static void MX_TIM1_Init(void);
static void MX_TIM3_Init(void);
static void MX_TIM4_Init(void);
static void MX_NVIC_Init(void);

int main(void)
{

  /* MCU Configuration--------------------------------------------------------*/

  /* Reset of all peripherals, Initializes the Flash interface and the Systick. */
  HAL_Init();

  /* Configure the system clock */
  SystemClock_Config();

  /* Initialize all configured peripherals */
  MX_GPIO_Init();
  MX_DMA_Init();
  MX_SPI1_Init();
  MX_CAN_Init();
  MX_ADC1_Init();
  MX_TIM1_Init();
  MX_TIM3_Init();
  MX_TIM4_Init();

	CalibTle5012b();

  MX_MotorControl_Init();

  /* Initialize interrupts */
  MX_NVIC_Init();
  /* USER CODE BEGIN 2 */

	HAL_GPIO_WritePin(VCC_ON_GPIO_Port,VCC_ON_Pin,GPIO_PIN_SET);  // ��������Դ

	MC_ProgramSpeedRampMotor1(200/6,200);
	// MC_ProgramTorqueRampMotor1(100,200);
	MC_StartMotor1();

  /* USER CODE END 2 */

  /* Infinite loop */
  while (1)
  {

  }
}

void SystemClock_Config(void)
{
  RCC_OscInitTypeDef RCC_OscInitStruct = {0};
  RCC_ClkInitTypeDef RCC_ClkInitStruct = {0};
  RCC_PeriphCLKInitTypeDef PeriphClkInit = {0};

  /**Initializes the CPU, AHB and APB busses clocks
  */
  RCC_OscInitStruct.OscillatorType = RCC_OSCILLATORTYPE_HSE;
  RCC_OscInitStruct.HSEState = RCC_HSE_ON;
  RCC_OscInitStruct.HSEPredivValue = RCC_HSE_PREDIV_DIV1;
  RCC_OscInitStruct.HSIState = RCC_HSI_ON;
  RCC_OscInitStruct.PLL.PLLState = RCC_PLL_ON;
  RCC_OscInitStruct.PLL.PLLSource = RCC_PLLSOURCE_HSE;
  RCC_OscInitStruct.PLL.PLLMUL = RCC_PLL_MUL9;
  if (HAL_RCC_OscConfig(&RCC_OscInitStruct) != HAL_OK)
  {
    Error_Handler();
  }
  /**Initializes the CPU, AHB and APB busses clocks
  */
  RCC_ClkInitStruct.ClockType = RCC_CLOCKTYPE_HCLK|RCC_CLOCKTYPE_SYSCLK
                              |RCC_CLOCKTYPE_PCLK1|RCC_CLOCKTYPE_PCLK2;
  RCC_ClkInitStruct.SYSCLKSource = RCC_SYSCLKSOURCE_PLLCLK;
  RCC_ClkInitStruct.AHBCLKDivider = RCC_SYSCLK_DIV1;
  RCC_ClkInitStruct.APB1CLKDivider = RCC_HCLK_DIV2;
  RCC_ClkInitStruct.APB2CLKDivider = RCC_HCLK_DIV1;

  if (HAL_RCC_ClockConfig(&RCC_ClkInitStruct, FLASH_LATENCY_2) != HAL_OK)
  {
    Error_Handler();
  }
  PeriphClkInit.PeriphClockSelection = RCC_PERIPHCLK_ADC;
  PeriphClkInit.AdcClockSelection = RCC_ADCPCLK2_DIV6;
  if (HAL_RCCEx_PeriphCLKConfig(&PeriphClkInit) != HAL_OK)
  {
    Error_Handler();
  }
  /**Enables the Clock Security System
  */
  HAL_RCC_EnableCSS();
}

/**
  * @brief NVIC Configuration.
  * @retval None
  */
static void MX_NVIC_Init(void)
{
  /* ADC1_2_IRQn interrupt configuration */
  HAL_NVIC_SetPriority(ADC1_2_IRQn, 2, 0);
  HAL_NVIC_EnableIRQ(ADC1_2_IRQn);
  /* TIM1_UP_IRQn interrupt configuration */
  HAL_NVIC_SetPriority(TIM1_UP_IRQn, 0, 0);
  HAL_NVIC_EnableIRQ(TIM1_UP_IRQn);
  /* TIM1_BRK_IRQn interrupt configuration */
  HAL_NVIC_SetPriority(TIM1_BRK_IRQn, 4, 1);
  HAL_NVIC_EnableIRQ(TIM1_BRK_IRQn);
  /* DMA1_Channel5_IRQn interrupt configuration */
  HAL_NVIC_SetPriority(DMA1_Channel5_IRQn, 0, 0);
  HAL_NVIC_EnableIRQ(DMA1_Channel5_IRQn);
  /* DMA1_Channel4_IRQn interrupt configuration */
  HAL_NVIC_SetPriority(DMA1_Channel4_IRQn, 0, 0);
  HAL_NVIC_EnableIRQ(DMA1_Channel4_IRQn);
  /* DMA1_Channel1_IRQn interrupt configuration */
  HAL_NVIC_SetPriority(DMA1_Channel1_IRQn, 0, 0);
  HAL_NVIC_EnableIRQ(DMA1_Channel1_IRQn);
  /* EXTI2_IRQn interrupt configuration */
  HAL_NVIC_SetPriority(EXTI2_IRQn, 0, 0);
  HAL_NVIC_EnableIRQ(EXTI2_IRQn);
}

static void MX_ADC1_Init(void)
{

  ADC_InjectionConfTypeDef sConfigInjected = {0};
  ADC_ChannelConfTypeDef sConfig = {0};

  /**Common config
  */
  hadc1.Instance = ADC1;
  hadc1.Init.ScanConvMode = ADC_SCAN_ENABLE;
  hadc1.Init.ContinuousConvMode = DISABLE;
  hadc1.Init.DiscontinuousConvMode = DISABLE;
  hadc1.Init.ExternalTrigConv = ADC_SOFTWARE_START;
  hadc1.Init.DataAlign = ADC_DATAALIGN_LEFT;
  hadc1.Init.NbrOfConversion = 1;
  if (HAL_ADC_Init(&hadc1) != HAL_OK)
  {
    Error_Handler();
  }
  /**Configure Injected Channel
  */
  sConfigInjected.InjectedChannel = ADC_CHANNEL_2;
  sConfigInjected.InjectedRank = ADC_INJECTED_RANK_1;
  sConfigInjected.InjectedNbrOfConversion = 2;
  sConfigInjected.InjectedSamplingTime = ADC_SAMPLETIME_7CYCLES_5;
  sConfigInjected.ExternalTrigInjecConv = ADC_EXTERNALTRIGINJECCONV_T4_TRGO;
  sConfigInjected.AutoInjectedConv = DISABLE;
  sConfigInjected.InjectedDiscontinuousConvMode = DISABLE;
  sConfigInjected.InjectedOffset = 0;
  if (HAL_ADCEx_InjectedConfigChannel(&hadc1, &sConfigInjected) != HAL_OK)
  {
    Error_Handler();
  }
  /**Configure Injected Channel
  */
  sConfigInjected.InjectedRank = ADC_INJECTED_RANK_2;
  if (HAL_ADCEx_InjectedConfigChannel(&hadc1, &sConfigInjected) != HAL_OK)
  {
    Error_Handler();
  }
  /**Configure Regular Channel
  */
  sConfig.Channel = ADC_CHANNEL_3;
  sConfig.Rank = ADC_REGULAR_RANK_1;
  sConfig.SamplingTime = ADC_SAMPLETIME_28CYCLES_5;
  if (HAL_ADC_ConfigChannel(&hadc1, &sConfig) != HAL_OK)
  {
    Error_Handler();
  }

}

static void MX_CAN_Init(void)
{

  hcan.Instance = CAN1;
  hcan.Init.Prescaler = 6;
  hcan.Init.Mode = CAN_MODE_NORMAL;
  hcan.Init.SyncJumpWidth = CAN_SJW_1TQ;
  hcan.Init.TimeSeg1 = CAN_BS1_3TQ;
  hcan.Init.TimeSeg2 = CAN_BS2_2TQ;
  hcan.Init.TimeTriggeredMode = DISABLE;
  hcan.Init.AutoBusOff = DISABLE;
  hcan.Init.AutoWakeUp = DISABLE;
  hcan.Init.AutoRetransmission = DISABLE;
  hcan.Init.ReceiveFifoLocked = DISABLE;
  hcan.Init.TransmitFifoPriority = DISABLE;
  if (HAL_CAN_Init(&hcan) != HAL_OK)
  {
    Error_Handler();
  }

}

static void MX_SPI1_Init(void)
{

  /* SPI1 parameter configuration*/
  hspi1.Instance = SPI1;
  hspi1.Init.Mode = SPI_MODE_MASTER;
  hspi1.Init.Direction = SPI_DIRECTION_2LINES;
  hspi1.Init.DataSize = SPI_DATASIZE_8BIT;
  hspi1.Init.CLKPolarity = SPI_POLARITY_LOW;
  hspi1.Init.CLKPhase = SPI_PHASE_1EDGE;
  hspi1.Init.NSS = SPI_NSS_SOFT;
  hspi1.Init.BaudRatePrescaler = SPI_BAUDRATEPRESCALER_8;
  hspi1.Init.FirstBit = SPI_FIRSTBIT_MSB;
  hspi1.Init.TIMode = SPI_TIMODE_DISABLE;
  hspi1.Init.CRCCalculation = SPI_CRCCALCULATION_DISABLE;
  hspi1.Init.CRCPolynomial = 10;
  if (HAL_SPI_Init(&hspi1) != HAL_OK)
  {
    Error_Handler();
  }

}

static void MX_TIM1_Init(void)
{

  TIM_SlaveConfigTypeDef sSlaveConfig = {0};
  TIM_MasterConfigTypeDef sMasterConfig = {0};
  TIM_OC_InitTypeDef sConfigOC = {0};
  TIM_BreakDeadTimeConfigTypeDef sBreakDeadTimeConfig = {0};

  htim1.Instance = TIM1;
  htim1.Init.Prescaler = ((TIM_CLOCK_DIVIDER) - 1);
  htim1.Init.CounterMode = TIM_COUNTERMODE_CENTERALIGNED3;
  htim1.Init.Period = ((PWM_PERIOD_CYCLES) / 2);
  htim1.Init.ClockDivision = TIM_CLOCKDIVISION_DIV2;
  htim1.Init.RepetitionCounter = (REP_COUNTER);
  htim1.Init.AutoReloadPreload = TIM_AUTORELOAD_PRELOAD_DISABLE;
  if (HAL_TIM_Base_Init(&htim1) != HAL_OK)
  {
    Error_Handler();
  }
  if (HAL_TIM_PWM_Init(&htim1) != HAL_OK)
  {
    Error_Handler();
  }
  sSlaveConfig.SlaveMode = TIM_SLAVEMODE_TRIGGER;
  sSlaveConfig.InputTrigger = TIM_TS_ITR1;
  if (HAL_TIM_SlaveConfigSynchronization(&htim1, &sSlaveConfig) != HAL_OK)
  {
    Error_Handler();
  }
  sMasterConfig.MasterOutputTrigger = TIM_TRGO_UPDATE;
  sMasterConfig.MasterSlaveMode = TIM_MASTERSLAVEMODE_DISABLE;
  if (HAL_TIMEx_MasterConfigSynchronization(&htim1, &sMasterConfig) != HAL_OK)
  {
    Error_Handler();
  }
  sConfigOC.OCMode = TIM_OCMODE_PWM1;
  sConfigOC.Pulse = 0;
  sConfigOC.OCPolarity = TIM_OCPOLARITY_HIGH;
  sConfigOC.OCNPolarity = TIM_OCNPOLARITY_HIGH;
  sConfigOC.OCFastMode = TIM_OCFAST_DISABLE;
  sConfigOC.OCIdleState = TIM_OCIDLESTATE_RESET;
  sConfigOC.OCNIdleState = TIM_OCNIDLESTATE_RESET;
  if (HAL_TIM_PWM_ConfigChannel(&htim1, &sConfigOC, TIM_CHANNEL_1) != HAL_OK)
  {
    Error_Handler();
  }
  if (HAL_TIM_PWM_ConfigChannel(&htim1, &sConfigOC, TIM_CHANNEL_2) != HAL_OK)
  {
    Error_Handler();
  }
  if (HAL_TIM_PWM_ConfigChannel(&htim1, &sConfigOC, TIM_CHANNEL_3) != HAL_OK)
  {
    Error_Handler();
  }
  sConfigOC.OCMode = TIM_OCMODE_PWM2;
  sConfigOC.Pulse = (((PWM_PERIOD_CYCLES) / 2) - (HTMIN));
  if (HAL_TIM_PWM_ConfigChannel(&htim1, &sConfigOC, TIM_CHANNEL_4) != HAL_OK)
  {
    Error_Handler();
  }
  sBreakDeadTimeConfig.OffStateRunMode = TIM_OSSR_ENABLE;
  sBreakDeadTimeConfig.OffStateIDLEMode = TIM_OSSI_ENABLE;
  sBreakDeadTimeConfig.LockLevel = TIM_LOCKLEVEL_1;
  sBreakDeadTimeConfig.DeadTime = 0;
  sBreakDeadTimeConfig.BreakState = TIM_BREAK_ENABLE;
  sBreakDeadTimeConfig.BreakPolarity = TIM_BREAKPOLARITY_LOW;
  sBreakDeadTimeConfig.AutomaticOutput = TIM_AUTOMATICOUTPUT_DISABLE;
  if (HAL_TIMEx_ConfigBreakDeadTime(&htim1, &sBreakDeadTimeConfig) != HAL_OK)
  {
    Error_Handler();
  }
  /* USER CODE BEGIN TIM1_Init 2 */
	TIM1->CCER |= 0x0555;
  /* USER CODE END TIM1_Init 2 */
  HAL_TIM_MspPostInit(&htim1);

}

static void MX_TIM3_Init(void)
{

  TIM_MasterConfigTypeDef sMasterConfig = {0};
  TIM_OC_InitTypeDef sConfigOC = {0};

  htim3.Instance = TIM3;
  htim3.Init.Prescaler = 0;
  htim3.Init.CounterMode = TIM_COUNTERMODE_UP;
  htim3.Init.Period = 0x800;
  htim3.Init.ClockDivision = TIM_CLOCKDIVISION_DIV1;
  htim3.Init.AutoReloadPreload = TIM_AUTORELOAD_PRELOAD_DISABLE;
  if (HAL_TIM_PWM_Init(&htim3) != HAL_OK)
  {
    Error_Handler();
  }
  sMasterConfig.MasterOutputTrigger = TIM_TRGO_RESET;
  sMasterConfig.MasterSlaveMode = TIM_MASTERSLAVEMODE_DISABLE;
  if (HAL_TIMEx_MasterConfigSynchronization(&htim3, &sMasterConfig) != HAL_OK)
  {
    Error_Handler();
  }
  sConfigOC.OCMode = TIM_OCMODE_PWM1;
  sConfigOC.Pulse = 0x400;
  sConfigOC.OCPolarity = TIM_OCPOLARITY_HIGH;
  sConfigOC.OCFastMode = TIM_OCFAST_DISABLE;
  if (HAL_TIM_PWM_ConfigChannel(&htim3, &sConfigOC, TIM_CHANNEL_3) != HAL_OK)
  {
    Error_Handler();
  }
  if (HAL_TIM_PWM_ConfigChannel(&htim3, &sConfigOC, TIM_CHANNEL_4) != HAL_OK)
  {
    Error_Handler();
  }
  HAL_TIM_MspPostInit(&htim3);

}

static void MX_TIM4_Init(void)
{

  TIM_SlaveConfigTypeDef sSlaveConfig = {0};
  TIM_MasterConfigTypeDef sMasterConfig = {0};
  TIM_OC_InitTypeDef sConfigOC = {0};

  htim4.Instance = TIM4;
  htim4.Init.Prescaler = ((TIM_CLOCK_DIVIDER) - 1);
  htim4.Init.CounterMode = TIM_COUNTERMODE_UP;
  htim4.Init.Period = ((PWM_PERIOD_CYCLES) - 1);
  htim4.Init.ClockDivision = TIM_CLOCKDIVISION_DIV2;
  htim4.Init.AutoReloadPreload = TIM_AUTORELOAD_PRELOAD_DISABLE;
  if (HAL_TIM_Base_Init(&htim4) != HAL_OK)
  {
    Error_Handler();
  }
  if (HAL_TIM_PWM_Init(&htim4) != HAL_OK)
  {
    Error_Handler();
  }
  sSlaveConfig.SlaveMode = TIM_SLAVEMODE_TRIGGER;
  sSlaveConfig.InputTrigger = TIM_TS_ITR1;
  if (HAL_TIM_SlaveConfigSynchronization(&htim4, &sSlaveConfig) != HAL_OK)
  {
    Error_Handler();
  }
  sMasterConfig.MasterOutputTrigger = TIM_TRGO_OC3REF;
  sMasterConfig.MasterSlaveMode = TIM_MASTERSLAVEMODE_DISABLE;
  if (HAL_TIMEx_MasterConfigSynchronization(&htim4, &sMasterConfig) != HAL_OK)
  {
    Error_Handler();
  }
  sConfigOC.OCMode = TIM_OCMODE_PWM2;
  sConfigOC.Pulse = 0;
  sConfigOC.OCPolarity = TIM_OCPOLARITY_HIGH;
  sConfigOC.OCFastMode = TIM_OCFAST_DISABLE;
  if (HAL_TIM_PWM_ConfigChannel(&htim4, &sConfigOC, TIM_CHANNEL_3) != HAL_OK)
  {
    Error_Handler();
  }

}

static void MX_DMA_Init(void)
{
  /* DMA controller clock enable */
  __HAL_RCC_DMA1_CLK_ENABLE();

}

static void MX_GPIO_Init(void)
{
  GPIO_InitTypeDef GPIO_InitStruct = {0};

  /* GPIO Ports Clock Enable */
  __HAL_RCC_GPIOD_CLK_ENABLE();
  __HAL_RCC_GPIOA_CLK_ENABLE();
  __HAL_RCC_GPIOB_CLK_ENABLE();

  /*Configure GPIO pin Output Level */
  HAL_GPIO_WritePin(SPI_CS_GPIO_Port, SPI_CS_Pin, GPIO_PIN_SET);

  /*Configure GPIO pin Output Level */
  HAL_GPIO_WritePin(VCC_ON_GPIO_Port, VCC_ON_Pin, GPIO_PIN_RESET);

  /*Configure GPIO pin Output Level */
  HAL_GPIO_WritePin(GPIOB, LED_1_Pin|LED_2_Pin, GPIO_PIN_SET);

  /*Configure GPIO pin : SPI_CS_Pin */
  GPIO_InitStruct.Pin = SPI_CS_Pin;
  GPIO_InitStruct.Mode = GPIO_MODE_OUTPUT_PP;
  GPIO_InitStruct.Pull = GPIO_NOPULL;
  GPIO_InitStruct.Speed = GPIO_SPEED_FREQ_LOW;
  HAL_GPIO_Init(SPI_CS_GPIO_Port, &GPIO_InitStruct);

  /*Configure GPIO pin : Start_Stop_Pin */
  GPIO_InitStruct.Pin = Start_Stop_Pin;
  GPIO_InitStruct.Mode = GPIO_MODE_IT_FALLING;
  GPIO_InitStruct.Pull = GPIO_NOPULL;
  HAL_GPIO_Init(Start_Stop_GPIO_Port, &GPIO_InitStruct);

  /*Configure GPIO pins : VCC_ON_Pin LED_1_Pin LED_2_Pin */
  GPIO_InitStruct.Pin = VCC_ON_Pin|LED_1_Pin|LED_2_Pin;
  GPIO_InitStruct.Mode = GPIO_MODE_OUTPUT_PP;
  GPIO_InitStruct.Pull = GPIO_NOPULL;
  GPIO_InitStruct.Speed = GPIO_SPEED_FREQ_LOW;
  HAL_GPIO_Init(GPIOB, &GPIO_InitStruct);

}

void Error_Handler(void)
{
}

/************************ (C) COPYRIGHT STMicroelectronics *****END OF FILE****/
